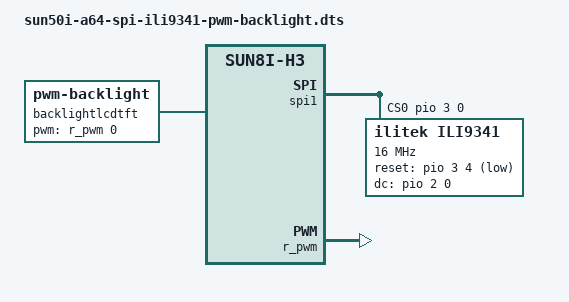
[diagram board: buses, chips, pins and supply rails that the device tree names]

/dts-v1/;
/plugin/;

/ {
	compatible = "allwinner,sun8i-h3";

  //ili9341

  fragment@0 {
    target = <&pio>;
    __overlay__ {
      ili9341_pins: ili9341_pins {
        pins = "PD4", "PC0"; /*RESET, DC_RS*/
        function = "gpio_out", "gpio_out" ;
      };
    };
  };
  
  fragment@1 {
    target = <&spi1>;
    __overlay__ {
      status = "okay";      
      cs-gpios = <&pio 3 0 0>; /* PD0 */

      ili9341: ili9341@0 {
        compatible = "ilitek,ili9341";
        reg = <0>;
        pinctrl-names = "default";
        pinctrl-0 = <&ili9341_pins>;
        spi-max-frequency = <16000000>;
        rotate = <90>;
        bgr;
        fps = <25>;
        buswidth = <8>;
        reset-gpios = <&pio 3 4 1>; /*RESET=PD4*/
        dc-gpios = <&pio 2 0 0>; /*DC_RS=PC0*/
        //backlight = <&backlightlcdtft>;
        /*led-gpios = <&pio 2 4 0>; LED=PC4*/
        debug = <0>;
      };
    };
  };

  //pwm-backlight

  fragment@2 {
        target = <&r_pwm>; /* PL10 */
        __overlay__ {
          status = "okay";
        };
  };
    
   fragment@3 {
      target-path = "/";
      __overlay__ {
        backlightlcdtft: backlightlcdtft {
          compatible = "pwm-backlight";
          pwms = <&r_pwm 0 5000000 0>;
          		  
		  brightness-levels = <0 8 16 32 48 64 80 96 160 224 255>;
          default-brightness-level = <8>;
		  
          //power-supply = <&reg_dcdc1>;
		  
          post-pwm-on-delay-ms = <10>;
          pwm-off-delay-ms = <10>;
        };
      };
    };

};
